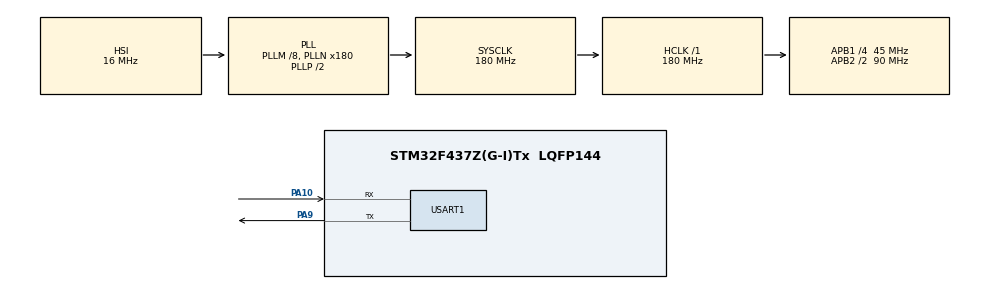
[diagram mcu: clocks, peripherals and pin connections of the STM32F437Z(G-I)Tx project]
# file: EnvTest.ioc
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FREERTOS.HEAP_NUMBER=4
FREERTOS.Tasks01=defaultTask,0,128,StartDefaultTask,Default,NULL
FREERTOS.configCHECK_FOR_STACK_OVERFLOW=1
Mcu.Family=STM32F4
Mcu.Name=STM32F437Z(G-I)Tx
Mcu.Package=LQFP144
NVIC.PriorityGroup=NVIC_PRIORITYGROUP_4
NVIC.TIM1_UP_TIM10_IRQn=true\:0\:0\:false\:false\:true\:false
NVIC.TimeBase=TIM1_UP_TIM10_IRQn
NVIC.TimeBaseIP=TIM1
PA10.Mode=Asynchronous
PA10.Signal=USART1_RX
PA13.Mode=Serial_Wire
PA13.Signal=SYS_JTMS-SWDIO
PA14.Mode=Serial_Wire
PA14.Signal=SYS_JTCK-SWCLK
PA9.Mode=Asynchronous
PA9.Signal=USART1_TX
PH0/OSC_IN.Mode=HSE-External-Oscillator
PH0/OSC_IN.Signal=RCC_OSC_IN
PH1/OSC_OUT.Mode=HSE-External-Oscillator
PH1/OSC_OUT.Signal=RCC_OSC_OUT
ProjectManager.HeapSize=0x200
ProjectManager.StackSize=0x400
ProjectManager.TargetToolchain=MDK-ARM V5
RCC.48MHZClocksFreq_Value=90000000
RCC.AHBFreq_Value=180000000
RCC.APB1CLKDivider=RCC_HCLK_DIV4
RCC.APB1Freq_Value=45000000
RCC.APB1TimFreq_Value=90000000
RCC.APB2CLKDivider=RCC_HCLK_DIV2
RCC.APB2Freq_Value=90000000
RCC.APB2TimFreq_Value=180000000
RCC.CortexFreq_Value=180000000
RCC.HCLKFreq_Value=180000000
RCC.HSE_VALUE=25000000
RCC.HSI_VALUE=16000000
RCC.LSE_VALUE=32768
RCC.PLLM=8
RCC.PLLN=180
RCC.SYSCLKFreq_VALUE=180000000
RCC.SYSCLKSource=RCC_SYSCLKSOURCE_PLLCLK
RCC.VCOOutputFreq_Value=360000000
USART1.VirtualMode=VM_ASYNC
VP_FREERTOS_VS_ENABLE.Mode=Enabled
VP_SYS_VS_tim1.Mode=TIM1
board=EnvTest

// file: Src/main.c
/**
  ******************************************************************************
  * File Name          : main.c
  * Description        : Main program body
  ******************************************************************************
  * This notice applies to any and all portions of this file
  * that are not between comment pairs USER CODE BEGIN and
  * USER CODE END. Other portions of this file, whether
  * inserted by the user or by software development tools
  * are owned by their respective copyright owners.
  *
  * Copyright (c) 2018 STMicroelectronics International N.V.
  * All rights reserved.
  *
  * Redistribution and use in source and binary forms, with or without
  * modification, are permitted, provided that the following conditions are met:
  *
  * 1. Redistribution of source code must retain the above copyright notice,
  *    this list of conditions and the following disclaimer.
  * 2. Redistributions in binary form must reproduce the above copyright notice,
  *    this list of conditions and the following disclaimer in the documentation
  *    and/or other materials provided with the distribution.
  * 3. Neither the name of STMicroelectronics nor the names of other
  *    contributors to this software may be used to endorse or promote products
  *    derived from this software without specific written permission.
  * 4. This software, including modifications and/or derivative works of this
  *    software, must execute solely and exclusively on microcontroller or
  *    microprocessor devices manufactured by or for STMicroelectronics.
  * 5. Redistribution and use of this software other than as permitted under
  *    this license is void and will automatically terminate your rights under
  *    this license.
  *
  * THIS SOFTWARE IS PROVIDED BY STMICROELECTRONICS AND CONTRIBUTORS "AS IS"
  * AND ANY EXPRESS, IMPLIED OR STATUTORY WARRANTIES, INCLUDING, BUT NOT
  * LIMITED TO, THE IMPLIED WARRANTIES OF MERCHANTABILITY, FITNESS FOR A
  * PARTICULAR PURPOSE AND NON-INFRINGEMENT OF THIRD PARTY INTELLECTUAL PROPERTY
  * RIGHTS ARE DISCLAIMED TO THE FULLEST EXTENT PERMITTED BY LAW. IN NO EVENT
  * SHALL STMICROELECTRONICS OR CONTRIBUTORS BE LIABLE FOR ANY DIRECT, INDIRECT,
  * INCIDENTAL, SPECIAL, EXEMPLARY, OR CONSEQUENTIAL DAMAGES (INCLUDING, BUT NOT
  * LIMITED TO, PROCUREMENT OF SUBSTITUTE GOODS OR SERVICES; LOSS OF USE, DATA,
  * OR PROFITS; OR BUSINESS INTERRUPTION) HOWEVER CAUSED AND ON ANY THEORY OF
  * LIABILITY, WHETHER IN CONTRACT, STRICT LIABILITY, OR TORT (INCLUDING
  * NEGLIGENCE OR OTHERWISE) ARISING IN ANY WAY OUT OF THE USE OF THIS SOFTWARE,
  * EVEN IF ADVISED OF THE POSSIBILITY OF SUCH DAMAGE.
  *
  ******************************************************************************
  */
#include "main.h"
#include "stm32f4xx_hal.h"
#include "cmsis_os.h"

/* USER CODE BEGIN Includes */
#include "search.h"
struct hsearch_data env_htab = {
	.change_ok = NULL,
};
/* USER CODE END Includes */

UART_HandleTypeDef huart1;

osThreadId defaultTaskHandle;

/* USER CODE BEGIN PV */
/* Private variables ---------------------------------------------------------*/

/* USER CODE END PV */

void SystemClock_Config(void);
static void MX_GPIO_Init(void);
static void MX_USART1_UART_Init(void);
void StartDefaultTask(void const * argument);

/* USER CODE BEGIN PFP */
/* Private function prototypes -----------------------------------------------*/

/* USER CODE END PFP */

/* USER CODE BEGIN 0 */
 int fputc(int ch, FILE *f)
 {
	HAL_UART_Transmit(&huart1, (uint8_t *)(&(ch)), 1, 10000);
	return 0;
 }
/* USER CODE END 0 */

int main(void)
{

  /* MCU Configuration----------------------------------------------------------*/

  /* Reset of all peripherals, Initializes the Flash interface and the Systick. */
  HAL_Init();

  /* Configure the system clock */
  SystemClock_Config();

  /* Initialize all configured peripherals */
  MX_GPIO_Init();
  MX_USART1_UART_Init();

  /* Create the thread(s) */
  /* definition and creation of defaultTask */
  osThreadDef(defaultTask, StartDefaultTask, osPriorityNormal, 0, 512);
  defaultTaskHandle = osThreadCreate(osThread(defaultTask), NULL);

  /* Start scheduler */
  osKernelStart();

  /* We should never get here as control is now taken by the scheduler */

  /* Infinite loop */
  while (1)
  {

  }

}

/** System Clock Configuration
*/
void SystemClock_Config(void)
{

  RCC_OscInitTypeDef RCC_OscInitStruct;
  RCC_ClkInitTypeDef RCC_ClkInitStruct;

    /**Configure the main internal regulator output voltage
    */
  __HAL_RCC_PWR_CLK_ENABLE();

  __HAL_PWR_VOLTAGESCALING_CONFIG(PWR_REGULATOR_VOLTAGE_SCALE1);

    /**Initializes the CPU, AHB and APB busses clocks
    */
  RCC_OscInitStruct.OscillatorType = RCC_OSCILLATORTYPE_HSI;
  RCC_OscInitStruct.HSIState = RCC_HSI_ON;
  RCC_OscInitStruct.HSICalibrationValue = 16;
  RCC_OscInitStruct.PLL.PLLState = RCC_PLL_ON;
  RCC_OscInitStruct.PLL.PLLSource = RCC_PLLSOURCE_HSI;
  RCC_OscInitStruct.PLL.PLLM = 8;
  RCC_OscInitStruct.PLL.PLLN = 180;
  RCC_OscInitStruct.PLL.PLLP = RCC_PLLP_DIV2;
  RCC_OscInitStruct.PLL.PLLQ = 4;
  if (HAL_RCC_OscConfig(&RCC_OscInitStruct) != HAL_OK)
  {
    _Error_Handler(__FILE__, __LINE__);
  }

    /**Activate the Over-Drive mode
    */
  if (HAL_PWREx_EnableOverDrive() != HAL_OK)
  {
    _Error_Handler(__FILE__, __LINE__);
  }

    /**Initializes the CPU, AHB and APB busses clocks
    */
  RCC_ClkInitStruct.ClockType = RCC_CLOCKTYPE_HCLK|RCC_CLOCKTYPE_SYSCLK
                              |RCC_CLOCKTYPE_PCLK1|RCC_CLOCKTYPE_PCLK2;
  RCC_ClkInitStruct.SYSCLKSource = RCC_SYSCLKSOURCE_PLLCLK;
  RCC_ClkInitStruct.AHBCLKDivider = RCC_SYSCLK_DIV1;
  RCC_ClkInitStruct.APB1CLKDivider = RCC_HCLK_DIV4;
  RCC_ClkInitStruct.APB2CLKDivider = RCC_HCLK_DIV2;

  if (HAL_RCC_ClockConfig(&RCC_ClkInitStruct, FLASH_LATENCY_5) != HAL_OK)
  {
    _Error_Handler(__FILE__, __LINE__);
  }

    /**Configure the Systick interrupt time
    */
  HAL_SYSTICK_Config(HAL_RCC_GetHCLKFreq()/1000);

    /**Configure the Systick
    */
  HAL_SYSTICK_CLKSourceConfig(SYSTICK_CLKSOURCE_HCLK);

  /* SysTick_IRQn interrupt configuration */
  HAL_NVIC_SetPriority(SysTick_IRQn, 15, 0);
}

/* USART1 init function */
static void MX_USART1_UART_Init(void)
{

  huart1.Instance = USART1;
  huart1.Init.BaudRate = 115200;
  huart1.Init.WordLength = UART_WORDLENGTH_8B;
  huart1.Init.StopBits = UART_STOPBITS_1;
  huart1.Init.Parity = UART_PARITY_NONE;
  huart1.Init.Mode = UART_MODE_TX_RX;
  huart1.Init.HwFlowCtl = UART_HWCONTROL_NONE;
  huart1.Init.OverSampling = UART_OVERSAMPLING_16;
  if (HAL_UART_Init(&huart1) != HAL_OK)
  {
    _Error_Handler(__FILE__, __LINE__);
  }

}

/** Configure pins as
        * Analog
        * Input
        * Output
        * EVENT_OUT
        * EXTI
*/
static void MX_GPIO_Init(void)
{

  /* GPIO Ports Clock Enable */
  __HAL_RCC_GPIOH_CLK_ENABLE();
  __HAL_RCC_GPIOA_CLK_ENABLE();

}

/* USER CODE BEGIN 4 */
void vApplicationStackOverflowHook(xTaskHandle xTask, signed char *pcTaskName)
{
	printf("Task stack overflow %s\r\n",pcTaskName);
}

const char default_environment[] = {
	"Hello=World""\0"
	"bootcmd=boot from spi0""\0"
};

env_t env;

static int env_print(char *name, int flag)
{
	char *res = NULL;
	ssize_t len;

	if (name) {		/* print a single name */
		ENTRY e, *ep;

		e.key = name;
		e.data = NULL;
		hsearch_r(e, FIND, &ep, &env_htab, flag);
		if (ep == NULL)
			return 0;
		len = printf("%s=%s\n", ep->key, ep->data);
		return len;
	}

	/* print whole list */
	len = hexport_r(&env_htab, '\n', flag, &res, 0, 0, NULL);

	if (len > 0) {
		printf("%s",res);
		vPortFree(res);
		return len;
	}

	/* should never happen */
	printf("## Error: cannot export environment\n");
	return 0;
}

char * testKey[] = {
	"hello",
	"helloworld",
	"google",
	"baidu",
	"baidu123456678",
};
int umm_test_main(void) ;
/* USER CODE END 4 */

/* StartDefaultTask function */
void StartDefaultTask(void const * argument)
{

	int i = 0;
	umm_test_main();

  /* USER CODE BEGIN 5 */
	printf("Initial heap size:0x%x\r\n",xPortGetFreeHeapSize());
	if (himport_r(&env_htab, (char *)default_environment, sizeof(default_environment),
				'\0', 0, 0, 0, NULL) == 0) {
		printf("Environment import failed\n");
	}
	printf("After set up hashtab remain heap size:0x%x\r\n", xPortGetFreeHeapSize());
	env_print("bootcmd",0);
	env_print("Hello",0);
	env_export(&env);
	printf("%s",env.data);
  /* Infinite loop */
  for(;;)
  {
		char * key = testKey[i];
		env_set(key,key);
		printf("set key %s, value:%s, remain heap size:0x%x\r\n",key,key,xPortGetFreeHeapSize());
		env_print(key,0);
		env_set(key,NULL);
		printf("After clear, remain heap size:0x%x\r\n",xPortGetFreeHeapSize());
		i=(i+1)%5;
    osDelay(1000);
  }
  /* USER CODE END 5 */
}

void HAL_TIM_PeriodElapsedCallback(TIM_HandleTypeDef *htim)
{
  if (htim->Instance == TIM1) {
    HAL_IncTick();
  }
}

void _Error_Handler(char * file, int line)
{
  while(1)
  {
  }
}

/************************ (C) COPYRIGHT STMicroelectronics *****END OF FILE****/
